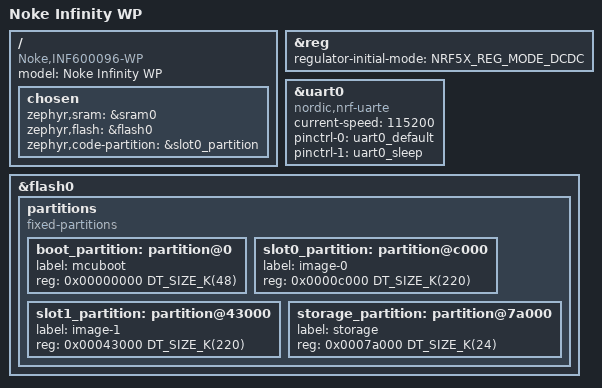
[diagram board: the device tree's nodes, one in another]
/dts-v1/;
#include <nordic/nrf52832_qfaa.dtsi>
#include "INF600096_WP-pinctrl.dtsi"

/ {
	model = "Noke Infinity WP";
	compatible = "Noke,INF600096-WP";

	chosen {
		zephyr,sram = &sram0;
		zephyr,flash = &flash0;
		zephyr,code-partition = &slot0_partition;
	};
};

&reg {
	regulator-initial-mode = <NRF5X_REG_MODE_DCDC>;
};

&uart0 {
	compatible = "nordic,nrf-uarte";
	status = "okay";
	current-speed = <115200>;
	pinctrl-0 = <&uart0_default>;
	pinctrl-1 = <&uart0_sleep>;
	pinctrl-names = "default", "sleep";
};

&flash0 {
	partitions {
		compatible = "fixed-partitions";
		#address-cells = <1>;
		#size-cells = <1>;

		boot_partition: partition@0 {
			label = "mcuboot";
			reg = <0x00000000 DT_SIZE_K(48)>;
		};

		slot0_partition: partition@c000 {
			label = "image-0";
			reg = <0x0000c000 DT_SIZE_K(220)>;
		};

		slot1_partition: partition@43000 {
			label = "image-1";
			reg = <0x00043000 DT_SIZE_K(220)>;
		};

		storage_partition: partition@7a000 {
			label = "storage";
			reg = <0x0007a000 DT_SIZE_K(24)>;
		};
	};
};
